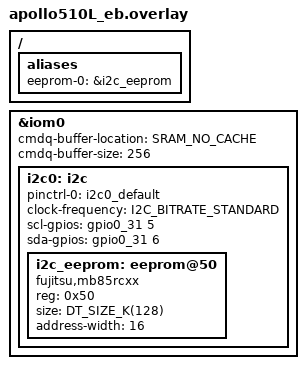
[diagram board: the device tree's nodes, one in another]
/*
 * Copyright (c) 2025, Ambiq Micro Inc. <www.ambiq.com>
 *
 * SPDX-License-Identifier: Apache-2.0
 */

/ {
	aliases {
		eeprom-0 = &i2c_eeprom;
	};
};

&iom0 {
	cmdq-buffer-location = "SRAM_NO_CACHE";
	cmdq-buffer-size = <256>;

	i2c0: i2c {
		pinctrl-0 = <&i2c0_default>;
		pinctrl-names = "default";
		clock-frequency = <I2C_BITRATE_STANDARD>;
		scl-gpios = <&gpio0_31 5 (GPIO_OPEN_DRAIN | GPIO_PULL_UP)>;
		sda-gpios = <&gpio0_31 6 (GPIO_OPEN_DRAIN | GPIO_PULL_UP)>;
		status = "okay";
		i2c_eeprom: eeprom@50 {
			compatible = "fujitsu,mb85rcxx";
			reg = <0x50>;
			size = <DT_SIZE_K(128)>;
			address-width = <16>;
		};
	};
};
